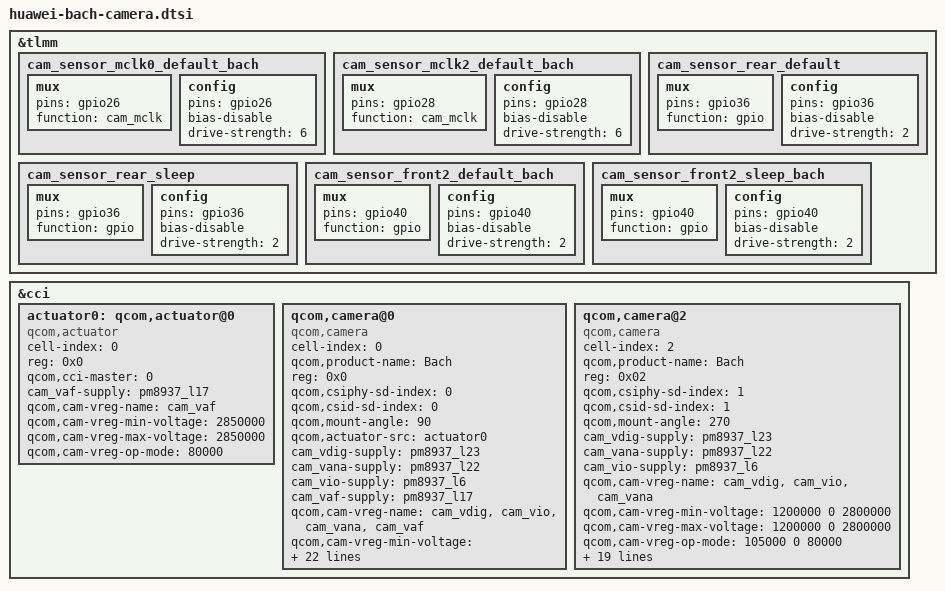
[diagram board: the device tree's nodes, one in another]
/*
 * Huawei BAH-W09 camera sensor configuration
 * Ported from 3.18 kernel (huawei-msm8940-camera-bah.dtsi)
 *
 * Rear camera (camera 0): CSIPHY 0, CSID 0, CCI master 0
 *   MCLK0 = GPIO 26, reset = GPIO 36
 *   AVDD enable = GPIO 132, DOVDD enable = GPIO 133
 *
 * Front camera (camera 2): CSIPHY 1, CSID 1, CCI master 1
 *   MCLK2 = GPIO 28, reset = GPIO 40
 *   AVDD enable = GPIO 132, DOVDD enable = GPIO 133
 */

&tlmm {
	cam_sensor_mclk0_default_bach: cam_sensor_mclk0_default_bach {
		mux {
			pins = "gpio26";
			function = "cam_mclk";
		};
		config {
			pins = "gpio26";
			bias-disable;
			drive-strength = <6>;
		};
	};

	cam_sensor_mclk2_default_bach: cam_sensor_mclk2_default_bach {
		mux {
			pins = "gpio28";
			function = "cam_mclk";
		};
		config {
			pins = "gpio28";
			bias-disable;
			drive-strength = <6>;
		};
	};

	cam_sensor_rear_default: cam_sensor_rear_default {
		mux {
			pins = "gpio36";
			function = "gpio";
		};
		config {
			pins = "gpio36";
			bias-disable;
			drive-strength = <2>;
		};
	};

	cam_sensor_rear_sleep: cam_sensor_rear_sleep {
		mux {
			pins = "gpio36";
			function = "gpio";
		};
		config {
			pins = "gpio36";
			bias-disable;
			drive-strength = <2>;
		};
	};

	cam_sensor_front2_default_bach: cam_sensor_front2_default_bach {
		mux {
			pins = "gpio40";
			function = "gpio";
		};
		config {
			pins = "gpio40";
			bias-disable;
			drive-strength = <2>;
		};
	};

	cam_sensor_front2_sleep_bach: cam_sensor_front2_sleep_bach {
		mux {
			pins = "gpio40";
			function = "gpio";
		};
		config {
			pins = "gpio40";
			bias-disable;
			drive-strength = <2>;
		};
	};
};

&cci {
	/*
	 * msm8940-mtp.dtsi includes the generic MTP camera sensor board file.
	 * Drop its EEPROM/third-camera graph so BAH-W09 does not probe sensors
	 * or calibration EEPROMs that are not present on this board.
	 */
	/delete-node/ qcom,actuator@1;
	/delete-node/ qcom,eeprom@0;
	/delete-node/ qcom,eeprom@1;
	/delete-node/ qcom,camera@1;

	actuator0: qcom,actuator@0 {
		cell-index = <0>;
		reg = <0x0>;
		compatible = "qcom,actuator";
		qcom,cci-master = <0>;
		cam_vaf-supply = <&pm8937_l17>;
		qcom,cam-vreg-name = "cam_vaf";
		qcom,cam-vreg-min-voltage = <2850000>;
		qcom,cam-vreg-max-voltage = <2850000>;
		qcom,cam-vreg-op-mode = <80000>;
	};

	qcom,camera@0 {
		/delete-property/ qcom,led-flash-src;
		/delete-property/ qcom,eeprom-src;

		cell-index = <0>;
		compatible = "qcom,camera";
		qcom,product-name = "Bach";
		reg = <0x0>;
		qcom,csiphy-sd-index = <0>;
		qcom,csid-sd-index = <0>;
		qcom,mount-angle = <90>;
		qcom,actuator-src = <&actuator0>;
		cam_vdig-supply = <&pm8937_l23>;
		cam_vana-supply = <&pm8937_l22>;
		cam_vio-supply = <&pm8937_l6>;
		cam_vaf-supply = <&pm8937_l17>;
		qcom,cam-vreg-name = "cam_vdig", "cam_vio", "cam_vana", "cam_vaf";
		qcom,cam-vreg-min-voltage = <1200000 0 2800000 2850000>;
		qcom,cam-vreg-max-voltage = <1200000 0 2800000 2850000>;
		qcom,cam-vreg-op-mode = <200000 0 80000 100000>;
		pinctrl-names = "cam_default", "cam_suspend";
		pinctrl-0 = <&cam_sensor_mclk0_default_bach
				&cam_sensor_rear_default>;
		pinctrl-1 = <&cam_sensor_mclk0_sleep
				&cam_sensor_rear_sleep>;
		gpios = <&tlmm 26 0>,
			<&tlmm 36 0>,
			<&tlmm 132 0>,
			<&tlmm 133 0>;
		qcom,gpio-reset = <1>;
		qcom,gpio-vana = <2>;
		qcom,gpio-vio = <3>;
		qcom,gpio-req-tbl-num = <0 1 2 3>;
		qcom,gpio-req-tbl-flags = <1 0 0 0>;
		qcom,gpio-req-tbl-label = "CAMIF_MCLK0",
			"CAM_RESET0",
			"CAM_AVDD_EN0",
			"CAM_DOVDD_EN0";
		qcom,sensor-position = <0>;
		qcom,sensor-mode = <0>;
		qcom,cci-master = <0>;
		status = "ok";
		clocks = <&clock_gcc clk_mclk0_clk_src>,
			<&clock_gcc clk_gcc_camss_mclk0_clk>;
		clock-names = "cam_src_clk", "cam_clk";
		qcom,clock-rates = <24000000 0>;
	};

	qcom,camera@2 {
		/delete-property/ qcom,eeprom-src;
		/delete-property/ qcom,actuator-src;

		cell-index = <2>;
		compatible = "qcom,camera";
		qcom,product-name = "Bach";
		reg = <0x02>;
		qcom,csiphy-sd-index = <1>;
		qcom,csid-sd-index = <1>;
		qcom,mount-angle = <270>;
		cam_vdig-supply = <&pm8937_l23>;
		cam_vana-supply = <&pm8937_l22>;
		cam_vio-supply = <&pm8937_l6>;
		qcom,cam-vreg-name = "cam_vdig", "cam_vio", "cam_vana";
		qcom,cam-vreg-min-voltage = <1200000 0 2800000>;
		qcom,cam-vreg-max-voltage = <1200000 0 2800000>;
		qcom,cam-vreg-op-mode = <105000 0 80000>;
		qcom,gpio-no-mux = <0>;
		pinctrl-names = "cam_default", "cam_suspend";
		pinctrl-0 = <&cam_sensor_mclk2_default_bach
				&cam_sensor_front2_default_bach>;
		pinctrl-1 = <&cam_sensor_mclk2_sleep
				&cam_sensor_front2_sleep_bach>;
		gpios = <&tlmm 28 0>,
			<&tlmm 40 0>,
			<&tlmm 132 0>,
			<&tlmm 133 0>;
		qcom,gpio-reset = <1>;
		qcom,gpio-vana = <2>;
		qcom,gpio-vio = <3>;
		qcom,gpio-req-tbl-num = <0 1 2 3>;
		qcom,gpio-req-tbl-flags = <1 0 0 0>;
		qcom,gpio-req-tbl-label = "CAMIF_MCLK2",
			"CAM_RESET2",
			"CAM_AVDD_EN2",
			"CAM_DOVDD_EN2";
		qcom,sensor-position = <1>;
		qcom,sensor-mode = <0>;
		qcom,cci-master = <1>;
		status = "ok";
		clocks = <&clock_gcc clk_mclk2_clk_src>,
			<&clock_gcc clk_gcc_camss_mclk2_clk>;
		clock-names = "cam_src_clk", "cam_clk";
		qcom,clock-rates = <24000000 0>;
	};
};
